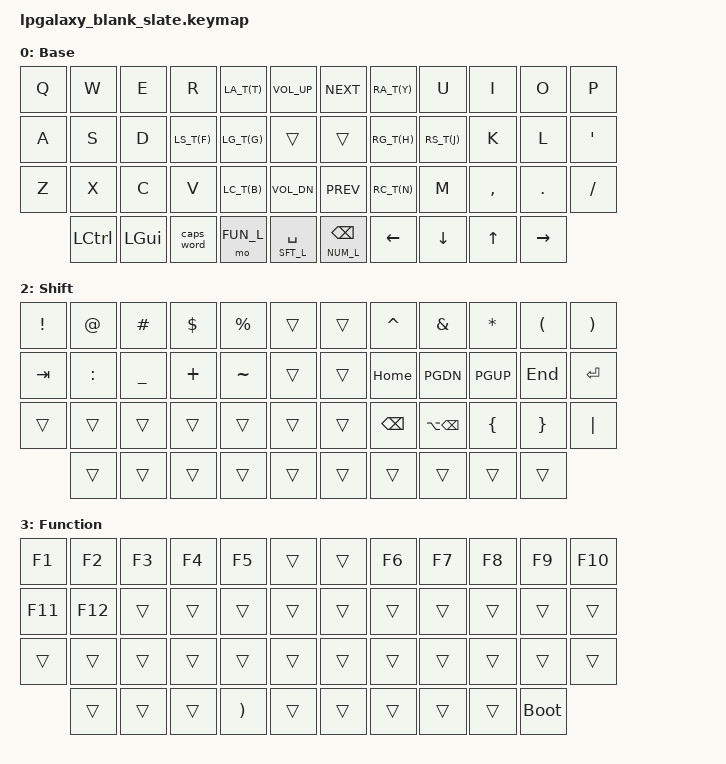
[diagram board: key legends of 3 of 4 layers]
/*
 * Copyright (c) 2022 Pete Johanson
 *
 * SPDX-License-Identifier: MIT
 */

#include <behaviors.dtsi>
#include <dt-bindings/zmk/keys.h>
#include <dt-bindings/zmk/bt.h>
#include <dt-bindings/zmk/outputs.h>
#include <dt-bindings/zmk/rgb.h>



#define QWERTY_BASE 1

// #define TBLE_ORTHO   1
// #define TBLE_MIT     1
#define TBLE_DUAL_2U 1

#define NUM_L 1
#define SFT_L 2
#define FUN_L 3

// Using layer taps on thumbs, having quick tap as well helps w/ repeating space/backspace
//&lt { quick_tap_ms = <100>; };

#define BT(n) BT_SEL n
#define LS_T(n) &ht LSHIFT n
#define RS_T(n) &ht RSHIFT n
#define LG_T(n) &ht LGUI n
#define RG_T(n) &ht RGUI n
#define LA_T(n) &ht LALT n
#define RA_T(n) &ht RALT n
#define RC_T(n) &ht RCTL n
#define LC_T(n) &ht LCTL n 

/ {
    chosen {
       zmk,physical-layout =
#ifdef TBLE_DUAL_2U
                       &layout_ortho_4x12_2x2u;
#elif defined(TBLE_MIT)
                       &layout_ortho_4x12_1x2u;
#else
                       &layout_ortho_4x12_all1u;
#endif
    };

    macros {
      ZMK_MACRO(thumbs_up,
                wait-ms = <1>;
                tap-ms = <5>;
                bindings = <&kp PLUS &kp COLON &kp PLUS &kp N1 &kp COLON &kp RET>;
                )
    };
    behaviors {
        ht: holdtap {
          compatible = "zmk,behavior-hold-tap";
          #binding-cells = <2>;
          flavor = "tap-preferred";
          tapping-term-ms = <180>;
          quick-tap-ms = <100>;
          require-prior-idle-ms = <65>;
          bindings = <&kp>, <&kp>;
        };
    };
    combos {
      compatible = "zmk,combos";
      combo_esc {
          timeout-ms = <50>;
          key-positions = <0 1>;
          bindings = <&kp ESC>;
        };
      combo_underscore {
          timeout-ms = <50>;
          key-positions = <40 41>;
          bindings = <&kp UNDER>;
        };
      combo_mute {
          timeout-ms = <50>;
          key-positions = <5 29>;
          bindings = <&kp C_MUTE>;
        };
      combo_next {
          timeout-ms = <50>;
          key-positions = <6 30>;
          bindings = <&kp C_NEXT>;
        };
    };

    keymap {
        compatible = "zmk,keymap";

        base_layer {
            label = "Base";
            bindings = <
#ifdef QWERTY_BASE
  //╭──────────┬──────────┬──────────┬──────────┬──────────╮                                      ╭──────────┬──────────┬──────────┬──────────┬──────────╮
  //│  Q       │  W       │  E       │  R       │  T       │                                      │  Y       │  U       │    I     │    O     │    P   
       &kp Q      &kp W      &kp E      &kp R     LA_T(T)          &kp C_VOL_UP   &kp C_NEXT        RA_T(Y)     &kp U    &kp I       &kp O      &kp P
  //├──────────┼──────────┼──────────┼──────────┼──────────┤                                      ├──────────┼──────────┼──────────┼──────────┼──────────┤
  //│  A       │  S       │  D       │  F       │  G       │                                      │  H       │  J       │  K       │  L       │    '     │
      &kp A      &kp S      &kp D       LS_T(F)    LG_T(G)          &trans         &trans            RG_T(H)     RS_T(J)     &kp K       &kp L      &kp QUOT  
  //├──────────┼──────────┼──────────┼──────────┼──────────┤                                      ├──────────┼──────────┼──────────┼──────────┼──────────┤
  //│    Z     │  X       │  C       │    V     │   B      │                                      │    N     │   M      │    , <   │ . >      │ / ?    
        &kp Z    &kp X      &kp C       &kp V     LC_T(B)          &kp C_VOL_DN   &kp C_PREV        RC_T(N)       &kp M     &kp COMMA    &kp DOT    &kp FSLH  
#else
 &kp ESC    &kp Q      &kp W      &kp F       &kp P          &kp B          &kp J            &kp L          &kp U       &kp Y      &kp QUOT      &kp BKSP
 &kp TAB    &kp A      &kp R      &kp S       &kp T          &kp G          &kp M            &kp N          &kp E       &kp I      &kp O         &kp QUOT
 &kp LSHFT  &kp Z      &kp X      &kp C       &kp D          &kp V          &kp K            &kp H          &kp COMMA   &kp DOT    &kp SEMI      &kp RET
#endif
#ifdef TBLE_DUAL_2U
 &kp LCTRL  &kp LGUI   &caps_word   &mo FUN_L         &lt SFT_L SPACE               &lt NUM_L BKSP          &kp LEFT &kp DOWN   &kp UP   &kp RIGHT
#elif defined(TBLE_MIT)
 &kp LCTRL  &mo SYM_L   &kp LGUI  &kp LALT    &mo NAV_L          &kp SPACE                   &mo NUM_L      &kp LEFT    &kp UP     &kp DOWN      &kp RIGHT
#else
 &kp LCTRL  &mo SYM_L   &kp LGUI  &kp LALT    &mo NAV_L      &kp SPACE      &kp RET          &mo NUM_L      &kp LEFT    &kp UP     &kp DOWN      &kp RIGHT
#endif
            >;
        };

        sym_layer {
            label = "Sym";
            bindings = <
//╭──────────┬──────────┬──────────┬──────────┬──────────╮                                      ╭──────────┬──────────┬──────────┬──────────┬──────────╮
    &kp N1    &kp N2     &kp N3     &kp N4      &kp N5             &trans       &trans              &kp N6     &kp N7     &kp N8     &kp N9     &kp N0
//├──────────┼──────────┼──────────┼──────────┼──────────┤                                      ├──────────┼──────────┼──────────┼──────────┼──────────┤
    &kp TAB     &kp SEMI   &kp MINUS  &kp EQUAL   &kp GRAVE        &trans       &trans              &kp LEFT  &kp DOWN   &kp UP    &kp RIGHT  &kp RET
//├──────────┼──────────┼──────────┼──────────┼──────────┤                                      ├──────────┼──────────┼──────────┼──────────┼──────────┤
   &bt BT_CLR  &bt BT(0)  &bt BT(1)  &bt BT(2)   &bt BT(3)         &trans       &trans              &kp BKSP  &kp LA(BKSP) &kp LBKT &kp RBKT  &kp BSLH
//├──────────┼──────────┼──────────┼──────────┼──────────┤                                      ├──────────┼──────────┼──────────┼──────────┼──────────┤
#ifdef TBLE_DUAL_2U
    &trans     &trans    &trans     &trans                   &kp LSHFT                 &trans                      &trans     &trans    &trans    &trans
#elif defined(TBLE_MIT)
&trans  &trans        &trans     &trans      &trans                &trans             &trans      &trans   &trans &trans &trans
#else
&trans  &trans        &trans     &trans      &trans          &trans       &trans    &trans  &trans         &trans &trans &trans
#endif
            >;
        };

        sft_layer {
            label = "Shift";
            bindings = <
//╭──────────┬──────────┬──────────┬──────────┬──────────╮                                      ╭──────────┬──────────┬──────────┬──────────┬──────────╮
    &kp EXCL   &kp AT     &kp HASH    &kp DLLR &kp PRCNT             &trans   &trans               &kp CARET  &kp AMPS  &kp ASTRK    &kp LPAR     &kp RPAR
//├──────────┼──────────┼──────────┼──────────┼──────────┤                                      ├──────────┼──────────┼──────────┼──────────┼──────────┤
    &kp TAB   &kp COLON  &kp UNDER   &kp PLUS   &kp TILDE            &trans    &trans              &kp HOME   &kp PGDN   &kp PGUP   &kp END     &kp RET
//├──────────┼──────────┼──────────┼──────────┼──────────┤                                      ├──────────┼──────────┼──────────┼──────────┼──────────┤
    &trans     &trans      &trans      &trans     &trans             &trans    &trans              &kp BKSP &kp LA(BKSP) &kp LBRC   &kp RBRC   &kp PIPE
#ifdef TBLE_DUAL_2U
    &trans     &trans      &trans      &trans                &trans                 &trans                  &trans       &trans     &trans     &trans
#elif defined(TBLE_MIT)
&trans  &trans       &trans     &kp N0      &trans           &none            &trans        &kp DEL      &trans &trans &trans
#else
&trans  &trans       &trans     &kp N0      &trans    &none         &none     &kp ESC        &kp DEL      &trans &trans &trans
#endif
            >;
        };

        fun_layer {
            label = "Function";
            bindings = <
//╭──────────┬──────────┬──────────┬──────────┬──────────╮                                      ╭──────────┬──────────┬──────────┬──────────┬──────────╮
   &kp F1     &kp F2     &kp F3      &kp F4    &kp F5                &trans     &trans             &kp F6    &kp F7       &kp F8      &kp F9   &kp F10
//├──────────┼──────────┼──────────┼──────────┼──────────┤                                      ├──────────┼──────────┼──────────┼──────────┼──────────┤
   &kp F11     &kp F12    &trans      &trans     &trans              &trans     &trans            &trans     &trans       &trans       &trans     &trans
//├──────────┼──────────┼──────────┼──────────┼──────────┤                                      ├──────────┼──────────┼──────────┼──────────┼──────────┤
   &trans     &trans     &trans       &trans    &trans               &trans     &trans             &trans    &trans       &trans       &trans     &trans
//├──────────┼──────────┼──────────┼──────────┼──────────┤                                      ├──────────┼──────────┼──────────┼──────────┼──────────┤
#ifdef TBLE_DUAL_2U
   &trans      &trans      &trans     &kp RPAR                &trans                    &trans       &trans         &trans &trans &bootloader
#elif defined(TBLE_MIT)
&trans &trans        &trans     &kp RPAR        &trans                &trans             &trans      &trans   &trans &trans &trans
#else
&trans &trans        &trans     &kp RPAR        &trans          &trans       &trans    &trans  &trans         &trans &trans &trans
#endif
            >;
        };


    };
};
